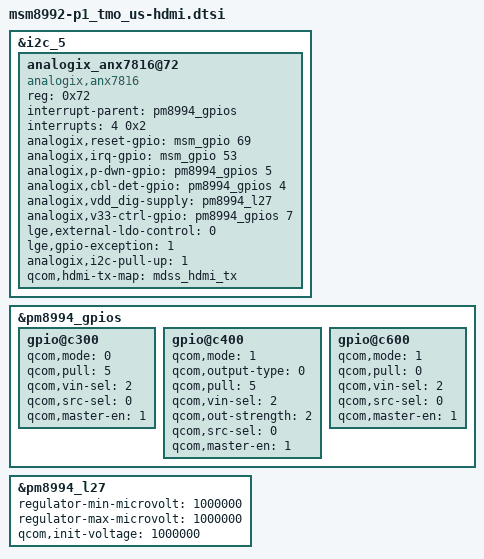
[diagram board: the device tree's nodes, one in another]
/* Copyright (c) 2012, Code Aurora Forum. All rights reserved.
 *
 * This program is free software; you can redistribute it and/or modify
 * it under the terms of the GNU General Public License version 2 and
 * only version 2 as published by the Free Software Foundation.
 *
 * This program is distributed in the hope that it will be useful,
 * but WITHOUT ANY WARRANTY; without even the implied warranty of
 * MERCHANTABILITY or FITNESS FOR A PARTICULAR PURPOSE.  See the
 * GNU General Public License for more details.
 */

&i2c_5{
	analogix_anx7816@72 {
		compatible = "analogix,anx7816";
		status = "ok";
		reg = <0x72>;
		interrupt-parent = <&pm8994_gpios>;
		interrupts = <4 0x2>; /* cbl-det-gpio is interrupt pin */
		analogix,reset-gpio = <&msm_gpio 69 0x00>;
		analogix,irq-gpio = <&msm_gpio 53 0x00>;
		analogix,p-dwn-gpio = <&pm8994_gpios 5 0x0>;
		analogix,cbl-det-gpio = <&pm8994_gpios 4 0x0>;
		analogix,vdd_dig-supply = <&pm8994_l27>;
		analogix,v33-ctrl-gpio = <&pm8994_gpios 7 0x0>;
		lge,external-ldo-control = <0>;
		lge,gpio-exception = <1>; /* for exception model */
		analogix,i2c-pull-up = <1>;
		qcom,hdmi-tx-map = <&mdss_hdmi_tx>;
	};
};
&pm8994_gpios {
	gpio@c300 {
		qcom,mode = <0>;
		qcom,pull = <5>;
		qcom,vin-sel = <2>;
		qcom,src-sel = <0>;
		qcom,master-en = <1>;
	};

	gpio@c400 {
		qcom,mode = <1>;
		qcom,output-type = <0>;
		qcom,pull = <5>;
		qcom,vin-sel = <2>;
		qcom,out-strength = <2>;
		qcom,src-sel = <0>;
		qcom,master-en = <1>;
	};
	gpio@c600 {
		qcom,mode = <1>;
		qcom,pull = <0>;
		qcom,vin-sel = <2>;
		qcom,src-sel = <0>;
		qcom,master-en = <1>;
	};
};


&pm8994_l27 {
	regulator-min-microvolt = <1000000>;
	regulator-max-microvolt = <1000000>;
	qcom,init-voltage = <1000000>;
};

